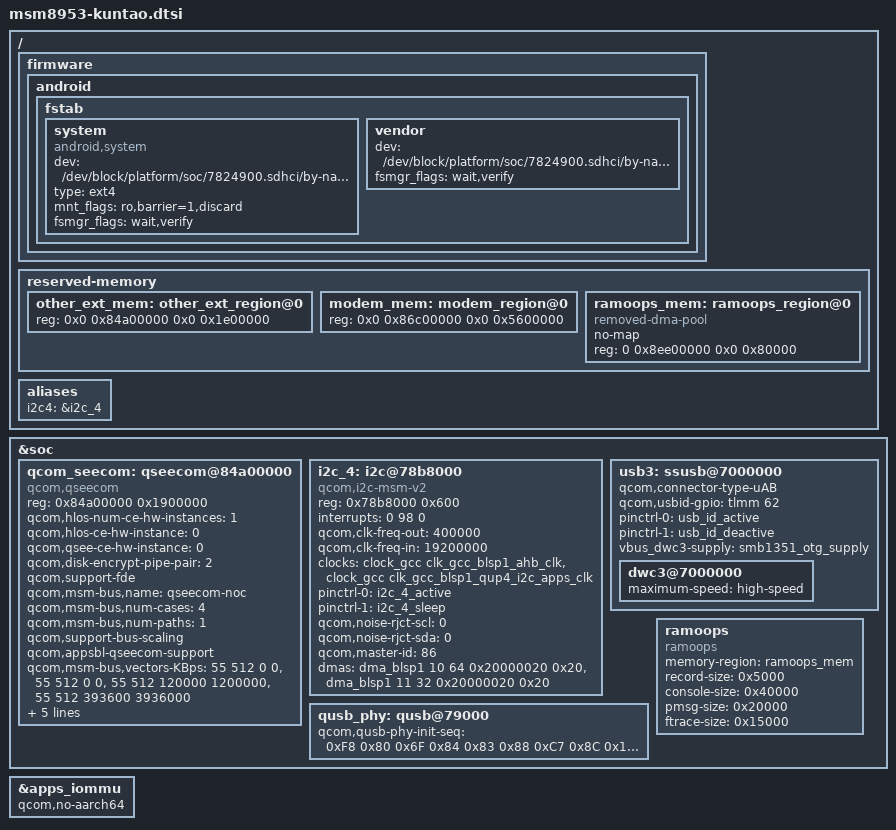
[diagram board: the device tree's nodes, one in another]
/*
 * Copyright (c) 2015-2018, The Linux Foundation. All rights reserved.
 *
 * This program is free software; you can redistribute it and/or modify
 * it under the terms of the GNU General Public License version 2 and
 * only version 2 as published by the Free Software Foundation.
 *
 * This program is distributed in the hope that it will be useful,
 * but WITHOUT ANY WARRANTY; without even the implied warranty of
 * MERCHANTABILITY or FITNESS FOR A PARTICULAR PURPOSE.  See the
 * GNU General Public License for more details.
 */

/ {
	firmware: firmware {
		android {
			/delete-node/ vbmeta;
			fstab {
				system {
					compatible = "android,system";
					dev = "/dev/block/platform/soc/7824900.sdhci/by-name/system";
					type = "ext4";
					mnt_flags = "ro,barrier=1,discard";
					fsmgr_flags = "wait,verify";
					status = "ok";
				};
				vendor {
					dev = "/dev/block/platform/soc/7824900.sdhci/by-name/preload";
					fsmgr_flags = "wait,verify";
				};
			};
		};
	};

	reserved-memory {
		other_ext_mem: other_ext_region@0 {
			reg = <0x0 0x84a00000 0x0 0x1e00000>;
		};

		modem_mem: modem_region@0 {
			reg = <0x0 0x86c00000 0x0 0x5600000>;
		};

		ramoops_mem: ramoops_region@0 {
			compatible = "removed-dma-pool";
			no-map;
			reg = <0 0x8ee00000 0x0 0x80000>;
		};
	};

	aliases {
		i2c4 = &i2c_4;
	};
};

&soc {
	/delete-node/ qseecom@85b00000;

	qcom_seecom: qseecom@84a00000 {
		compatible = "qcom,qseecom";
		reg = <0x84a00000 0x1900000>;
		reg-names = "secapp-region";
		qcom,hlos-num-ce-hw-instances = <1>;
		qcom,hlos-ce-hw-instance = <0>;
		qcom,qsee-ce-hw-instance = <0>;
		qcom,disk-encrypt-pipe-pair = <2>;
		qcom,support-fde;
		qcom,msm-bus,name = "qseecom-noc";
		qcom,msm-bus,num-cases = <4>;
		qcom,msm-bus,num-paths = <1>;
		qcom,support-bus-scaling;
		qcom,appsbl-qseecom-support;
		qcom,msm-bus,vectors-KBps =
			<55 512 0 0>,
			<55 512 0 0>,
			<55 512 120000 1200000>,
			<55 512 393600 3936000>;
		clocks = <&clock_gcc clk_crypto_clk_src>,
			 <&clock_gcc clk_gcc_crypto_clk>,
			 <&clock_gcc clk_gcc_crypto_ahb_clk>,
			 <&clock_gcc clk_gcc_crypto_axi_clk>;
		clock-names = "core_clk_src", "core_clk",
				"iface_clk", "bus_clk";
		qcom,ce-opp-freq = <100000000>;
		status = "okay";
	};

	i2c_4: i2c@78b8000 { /* BLSP1 QUP4 */
		compatible = "qcom,i2c-msm-v2";
		#address-cells = <1>;
		#size-cells = <0>;
		reg-names = "qup_phys_addr";
		reg = <0x78b8000 0x600>;
		interrupt-names = "qup_irq";
		interrupts = <0 98 0>;
		qcom,clk-freq-out = <400000>;
		qcom,clk-freq-in  = <19200000>;
		clock-names = "iface_clk", "core_clk";
		clocks = <&clock_gcc clk_gcc_blsp1_ahb_clk>,
			 <&clock_gcc clk_gcc_blsp1_qup4_i2c_apps_clk>;

		pinctrl-names = "i2c_active", "i2c_sleep";
		pinctrl-0 = <&i2c_4_active>;
		pinctrl-1 = <&i2c_4_sleep>;
		qcom,noise-rjct-scl = <0>;
		qcom,noise-rjct-sda = <0>;
		qcom,master-id = <86>;
		dmas = <&dma_blsp1 10 64 0x20000020 0x20>,
			<&dma_blsp1 11 32 0x20000020 0x20>;
		dma-names = "tx", "rx";
	};

	usb3: ssusb@7000000{
		qcom,connector-type-uAB;
		qcom,usbid-gpio = <&tlmm 62 0>;
		pinctrl-names = "usbid_default", "usbid_deactive";
		pinctrl-0 = <&usb_id_active>;
		pinctrl-1 = <&usb_id_deactive>;
		vbus_dwc3-supply = <&smb1351_otg_supply>;

		dwc3@7000000 {
			maximum-speed = "high-speed";
		};
	};

	qusb_phy: qusb@79000 {
		qcom,qusb-phy-init-seq = <0xF8 0x80
					0x6F 0x84
					0x83 0x88
					0xC7 0x8C
					0x14 0x9C
					0x30 0x08
					0x79 0x0C
					0x21 0x10
					0x03 0x90
					0x9F 0x1C
					0x00 0x18>;
	};

	ramoops {
		compatible = "ramoops";
		memory-region = <&ramoops_mem>;
		record-size = <0x5000>;
		console-size = <0x40000>;
		pmsg-size = <0x20000>;
		ftrace-size = <0x15000>;
	};
};

&apps_iommu {
	qcom,no-aarch64;
};

